# haltium_secure register map
Vendor: Nordic Semiconductor; Series: nRFHaltium; File version: 1
CPU: CM33 r0p4, little endian, MPU, FPU, 3 interrupt priority bits, 480 interrupts
Registers are 32-bit, read-write, reset 0x0 unless marked. A register's access mark holds for its fields unless they carry their own. Offsets are from the block's base; [hi:lo] are bit positions; lines under a group give offsets from that group; {n}, {i} and the like mark numbered series.

## LRCCONF200_S — LRCCONF 0
Base 0xBF005000
Same registers: LRCCONF000_S 0x5100E000, LRCCONF010_S 0x5101E000
{0x0+4i} TASKS_CLKSTART[{i}] (i=0..7) wo — Description collection: Start the clock source [n]
  [0] TASKS_CLKSTART — Start the clock source [n]
    1=Trigger task
{0x20+4i} TASKS_CLKSTOP[{i}] (i=0..7) wo — Description collection: Clear the TASKS_CLKSTART[n] request
  [0] TASKS_CLKSTOP — Clear the TASKS_CLKSTART[n] request
    1=Trigger task
0x40 TASKS_CONSTLAT wo — Enable constant latency mode
  [0] TASKS_CONSTLAT
    1=Trigger task
0x44 TASKS_LOWPWR wo — Enable Low Power mode
  [0] TASKS_LOWPWR
    1=Trigger task
{0x100+4i} EVENTS_CLKSTARTED[{i}] (i=0..7) — Description collection: Clock [n] started
  [0] EVENTS_CLKSTARTED — Clock [n] started
    0=NotGenerated (Event not generated); 1=Generated (Event generated)
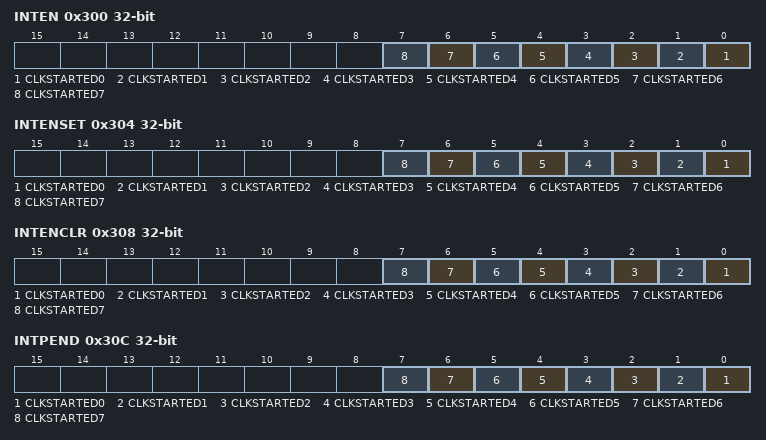
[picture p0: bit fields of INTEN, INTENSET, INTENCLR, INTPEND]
0x300 INTEN — Enable or disable interrupt
  [all] fields
    0=Disabled; 1=Enabled
  [n] CLKSTARTED{n} (n=0..7) — Enable or disable interrupt for event CLKSTARTED[{n}]
0x304 INTENSET — Enable interrupt
  [all] fields
    on read: 0=Disabled (Read: Disabled); 1=Enabled (Read: Enabled) | on write: 1=Set (Enable)
  [n] CLKSTARTED{n} (n=0..7) — Write '1' to enable interrupt for event CLKSTARTED[{n}]
0x308 INTENCLR — Disable interrupt
  [all] fields
    on read: 0=Disabled (Read: Disabled); 1=Enabled (Read: Enabled) | on write: 1=Clear (Disable)
  [n] CLKSTARTED{n} (n=0..7) — Write '1' to disable interrupt for event CLKSTARTED[{n}]
0x30C INTPEND ro — Pending interrupts
  [all] fields
    on read: 0=NotPending (Read: Not pending); 1=Pending (Read: Pending)
  [n] CLKSTARTED{n} (n=0..7) — Read pending status of interrupt for event CLKSTARTED[{n}]
{0x400+8i} CLKSTAT[{i}] (i=0..6) group — Unspecified
  0x00 RUN — Description cluster: Status indicating that TASKS_START task has been triggered for clock [n].
    [0] STATUS ro — Clock start task triggered or not
      0=NotTriggered (Task not triggered); 1=Triggered (Task triggered)
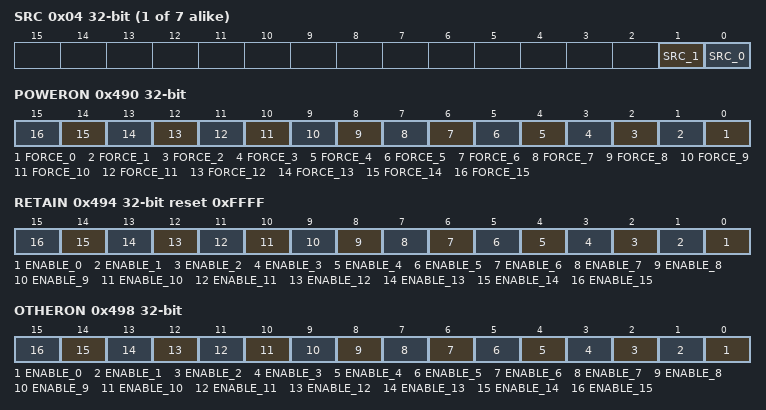
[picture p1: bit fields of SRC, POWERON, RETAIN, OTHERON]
  0x04 SRC — Description cluster: Status indicating which clock source is running for clock [n]
    [1] SRC_1 — Clock source
    [0] SRC_0 — Clock source
{0x440+8i} CLKCTRL[{i}] (i=0..6) group — Unspecified
  0x00 ALWAYSRUN — Description cluster: Force the clock source [n] and tree running always
    [0] FORCE — Force the clock always running
      0=Automatic clock control enabled; 1=AlwaysRun (Clock always running)
  0x04 SRC — Description cluster: Select the clock source for clock [n]
    [1] SRC_1 — Clock source
    [0] SRC_0 — Clock source
0x480 CONSTLATSTAT ro — Status of constant latency
  [0] STATUS
    0=Low power enabled; 1=ConstLat (Constant latency enabled)
0x490 POWERON — Force power domain ON
  [all] fields
    0=Automatic power control enabled; 1=AlwaysOn (Keep the power domain ON to the domain even though there is no request)
  [n] FORCE_{n} (n=0..15) — Force the power domain ON for domain[{n}]
0x494 RETAIN reset 0xFFFF — Retain power domain
  [all] fields
    0=Disable (Retain disabled); 1=Enable (retain enabled)
  [n] ENABLE_{n} (n=0..15) — Retain the power domain on for domain[{n}]
0x498 OTHERON — Request other domain ON
  [all] fields
    0=Automatic power control enabled; 1=AlwaysOn (Request to keep the other power domain ON to the domain even though there is no request)
  [n] ENABLE_{n} (n=0..15) — Request power domain ON for other domain[{n}]
0x4A0 RESETREAS group — Unspecified
  0x00 GLOBALCOPY write-1-clears — Copy of the global reset reason.
    [31:0] GLOBAL — Global reset reason
  0x04 DOMAINCOPY write-1-clears — Copy of the domain reset reason.
    [31:0] DOMAIN — Domain reset reason
  0x08 RESETSTATUS write-1-clears
    [31:0] ERRORCODE
{0x500+4i} AX2XWAITSTATES[{i}] (i=0..15) — Description collection: AX2X bridge waitstates for the domain[n], where n is domain id.
  [2:0] WAITSTATES — Number of waitstates
